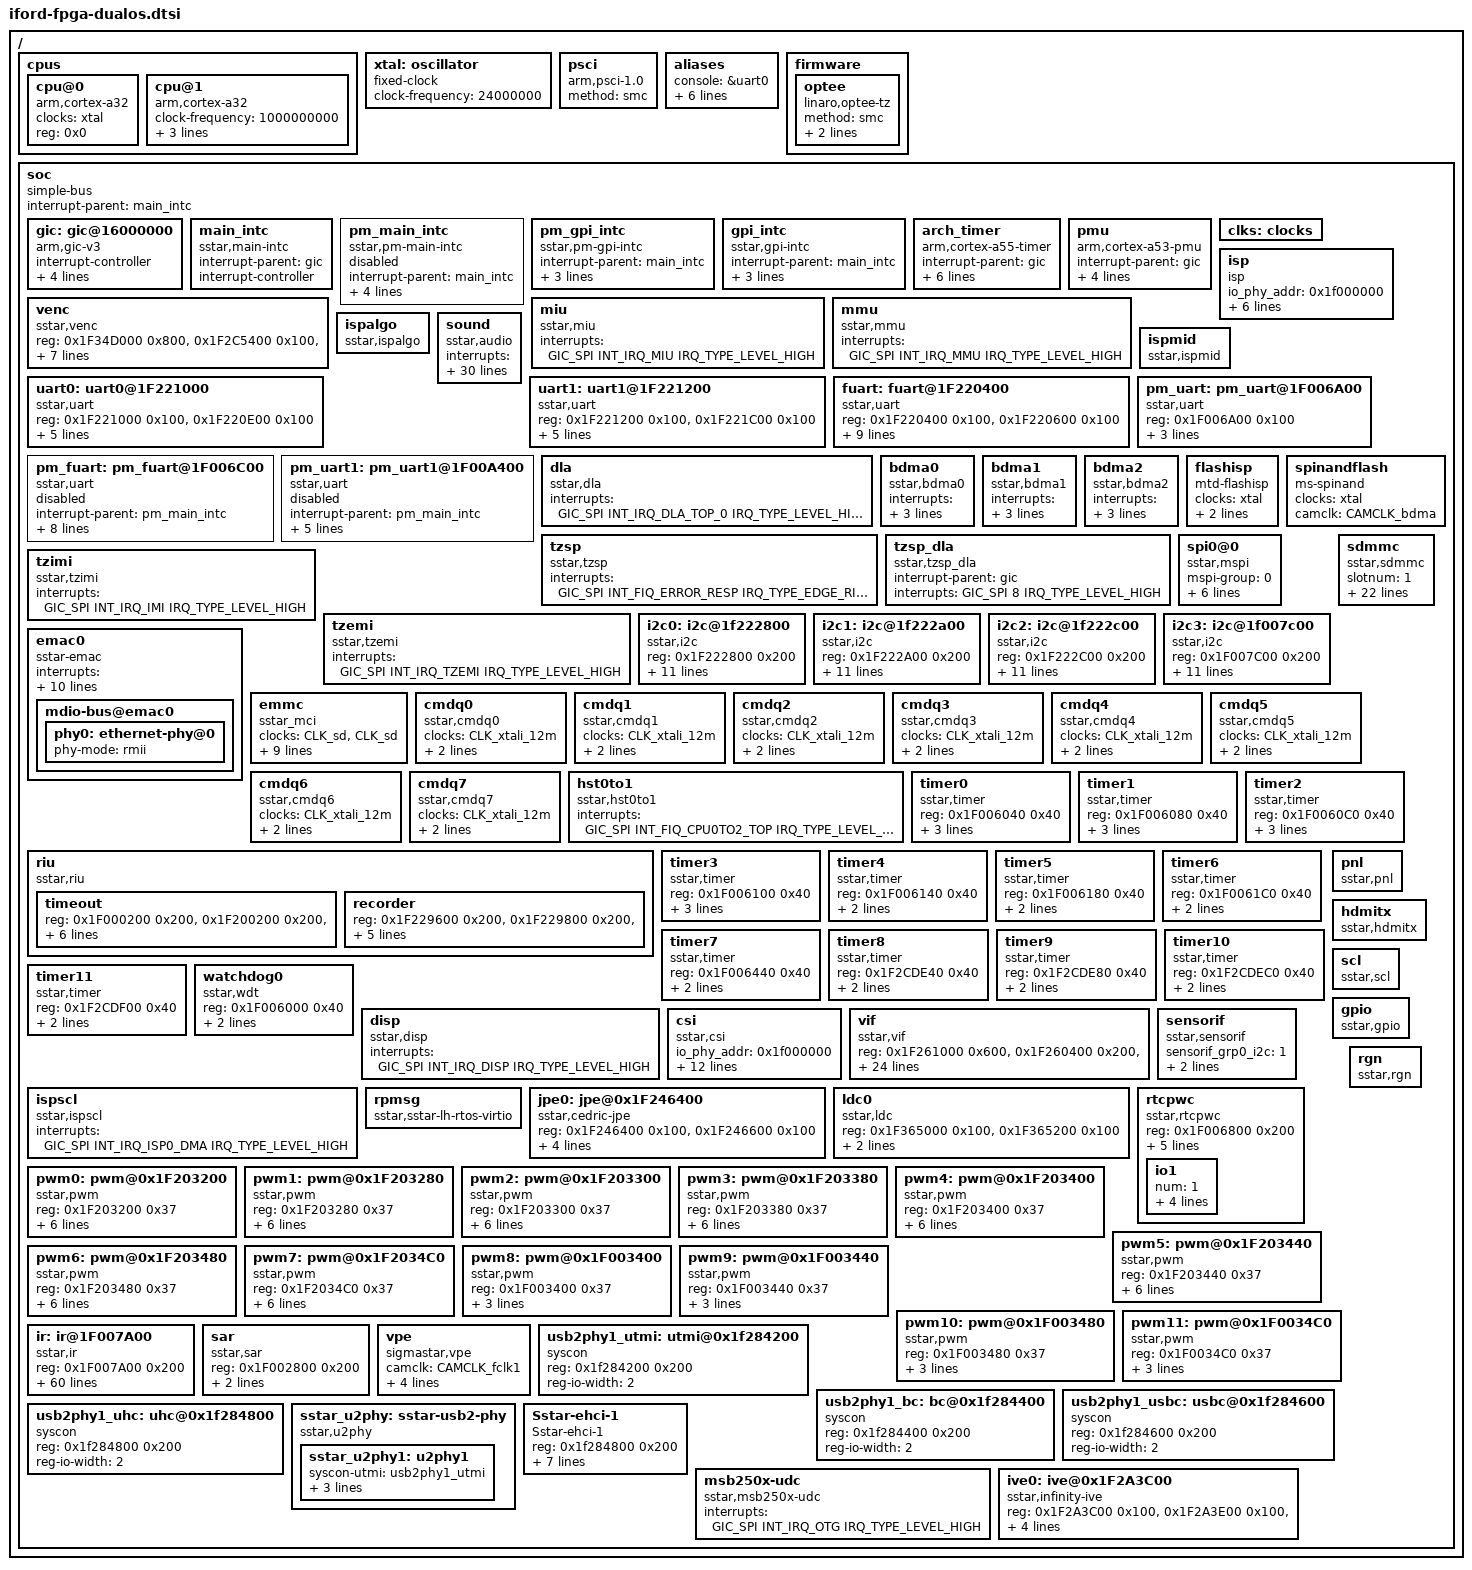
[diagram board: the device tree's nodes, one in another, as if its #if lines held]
/*
* iford-fpga.dtsi- Sigmastar
*
* Copyright (c) [2019~2020] SigmaStar Technology.
*
*
* This software is licensed under the terms of the GNU General Public
* License version 2, as published by the Free Software Foundation, and
* may be copied, distributed, and modified under those terms.
*
* This program is distributed in the hope that it will be useful,
* but WITHOUT ANY WARRANTY; without even the implied warranty of
* MERCHANTABILITY or FITNESS FOR A PARTICULAR PURPOSE.  See the
* GNU General Public License version 2 for more details.
*
*/
#include "../../../../include/generated/autoconf.h"
#include "../../../../drivers/sstar/include/iford/irqs-fpga.h"
#include "../../../../drivers/sstar/include/iford/pmsleep-irqs.h"
#include "../../../../drivers/sstar/include/iford/gpio.h"
#include <dt-bindings/interrupt-controller/irq.h>
#include <dt-bindings/interrupt-controller/arm-gic.h>
#include <dt-bindings/input/input.h>

/ {
    cpus {
        #address-cells = <1>;
        #size-cells = <0>;

        cpu@0 {
            device_type = "cpu";
            compatible = "arm,cortex-a32";
            clocks = <&xtal>;
            reg = <0x0>;
        };

#ifdef CONFIG_SMP
        cpu@1 {
            device_type = "cpu";
            compatible = "arm,cortex-a32";
            clock-frequency = <1000000000>;
            clocks = <&xtal>;
            reg = <0x1>;
#if CONFIG_ENABLE_METHOD_PSCI
            enable-method = "psci";
#endif
        };
#endif
    };

    xtal: oscillator {
        compatible = "fixed-clock";
        #clock-cells = <0>;
        clock-frequency = <24000000>;
    };

#if CONFIG_ARM_PSCI
    psci {
        compatible = "arm,psci-1.0";
        method = "smc";
    };
#endif

    aliases {
        console = &uart0;
        serial0 = &uart0;
        serial1 = &uart1;
        serial2 = &fuart;
        serial3 = &pm_uart;
        serial4 = &pm_fuart;
        serial5 = &pm_uart1;
    };

#ifdef CONFIG_OPTEE
    firmware {
        optee {
            compatible = "linaro,optee-tz";
            method = "smc";
            #interrupt-cells = <3>;
            interrupt-parent = <&gic>;
            interrupts = <GIC_SPI 31 IRQ_TYPE_EDGE_RISING>;
        };
    };
#endif

    soc {
        compatible = "simple-bus";
        interrupt-parent = <&main_intc>;
        #address-cells = <1>;
        #size-cells = <1>;
        ranges;

        gic: gic@16000000 {
            compatible = "arm,gic-v3";
            #interrupt-cells = <3>;
            #address-cells = <1>;
            #size-cells = <1>;
            interrupt-controller;
            interrupt-parent = <&gic>;
            redistributor-stride = <0x0 0x20000>;
            #redistributor-regions = <1>;
            reg = <0x16000000 0x20000>,
                  <0x16040000 0x40000>;
        };

        main_intc: main_intc {
            compatible = "sstar,main-intc";
            #interrupt-cells = <3>;
            #address-cells = <1>;
            #size-cells = <1>;
            interrupt-parent=<&gic>;
            interrupt-controller;
        };

        pm_main_intc: pm_main_intc {
            compatible = "sstar,pm-main-intc";
            #interrupt-cells = <1>;
            interrupt-parent=<&main_intc>;
            interrupt-controller;
            interrupts = <GIC_SPI INT_FIQ_FIQ_FROM_PM IRQ_TYPE_LEVEL_HIGH>, <GIC_SPI INT_IRQ_IRQ2HST_0 IRQ_TYPE_LEVEL_HIGH>;
            status = "disabled";
        };

        pm_gpi_intc: pm_gpi_intc {
            compatible = "sstar,pm-gpi-intc";
            #interrupt-cells = <1>;
            interrupt-parent=<&main_intc>;
            interrupt-controller;
            interrupts = <GIC_SPI INT_IRQ_PM_SLEEP IRQ_TYPE_LEVEL_HIGH>;
        };

        gpi_intc: gpi_intc {
            compatible = "sstar,gpi-intc";
            #interrupt-cells = <1>;
            interrupt-parent=<&main_intc>;
            interrupt-controller;
            interrupts = <GIC_SPI INT_IRQ_GPI_OUT IRQ_TYPE_LEVEL_HIGH>;
        };

        arch_timer {
            compatible = "arm,cortex-a55-timer", "arm,armv8-timer";
            interrupt-parent=<&gic>;
            interrupts = <GIC_PPI 13 (GIC_CPU_MASK_SIMPLE(2) | IRQ_TYPE_LEVEL_LOW)>,
                         <GIC_PPI 14 (GIC_CPU_MASK_SIMPLE(2) | IRQ_TYPE_LEVEL_LOW)>,
                         <GIC_PPI 11 (GIC_CPU_MASK_SIMPLE(2) | IRQ_TYPE_LEVEL_LOW)>,
                         <GIC_PPI 10 (GIC_CPU_MASK_SIMPLE(2) | IRQ_TYPE_LEVEL_LOW)>;
            clock-frequency = <6000000>;  /* arch_timer must use clock-frequency*/
        };

        pmu {
            compatible = "arm,cortex-a53-pmu";
            interrupt-parent=<&gic>;
            interrupts = <GIC_SPI 10 IRQ_TYPE_LEVEL_HIGH>,
                         <GIC_SPI 16 IRQ_TYPE_LEVEL_HIGH>,
                         <GIC_SPI 22 IRQ_TYPE_LEVEL_HIGH>,
                         <GIC_SPI 28 IRQ_TYPE_LEVEL_HIGH>;
        };

        clks: clocks{
            #address-cells = <1>;
            #size-cells = <1>;
            ranges;
        };
        venc {
            compatible = "sstar,venc";
            reg = <0x1F34D000 0x800>, <0x1F2C5400 0x100>, <0x1F203C00 0x100>, <0x1F207800 0x100>, <0x1F2C5400 0x100>;
            reg-names = "vpu-bit", "venc-brige", "hw-uart0", "hw-uart1", "venc-gp";
            interrupts = <GIC_SPI INT_IRQ_MHE_0 IRQ_TYPE_LEVEL_HIGH>;
            interrupt-parent = <&main_intc>;
            interrupt-names = "mhe-irq";
            clocks = <&CLK_vhe>, <&CLK_mfe>, <&CLK_ven_axi>,<&CLK_ven_scdn>,<&CLK_ven_sc_if>;
            clock-names = "CKG_venc";
            status = "ok";
        };

        miu {
            compatible = "sstar,miu";
            interrupts=<GIC_SPI INT_IRQ_MIU IRQ_TYPE_LEVEL_HIGH>;
            status = "ok";
        };

        mmu {
            compatible = "sstar,mmu";
            interrupts=<GIC_SPI INT_IRQ_MMU IRQ_TYPE_LEVEL_HIGH>;
            status = "ok";
        };

        isp: isp {
            compatible = "isp";
            io_phy_addr = <0x1f000000>;
            banks = <0x1302>;
            interrupts = <GIC_SPI INT_IRQ_ISP_0 IRQ_TYPE_LEVEL_HIGH>;
            clocks = <&CLK_isp>,<&CLK_fclk1>,<&CLK_dsc_enc1>,<&CLK_dsc_dec1>;
            status = "ok";
            clock-frequency-index = <0>;
        };

        ispalgo: ispalgo {
            compatible = "sstar,ispalgo";
            status = "ok";
        };

/*
        ispscl: ispscl {
            compatible = "sstar,ispscl";
            interrupts = <GIC_SPI INT_IRQ_ISP0_DMA IRQ_TYPE_LEVEL_HIGH>;
            status = "ok";
        };
*/

        ispmid: ispmid {
            compatible = "sstar,ispmid";
            status = "ok";
        };

/*
        timer_clockevent: timer@1F006040 {
            compatible = "sstar,piu-clockevent";
            reg = <0x1F006040 0x100>;
            interrupts=<GIC_SPI INT_FIQ_TIMER_0 IRQ_TYPE_LEVEL_HIGH>;
            clocks = <&CLK_xtali_12m>;
        };
*/
        sound {
            compatible = "sstar,audio";
            interrupts=<GIC_SPI INT_IRQ_BACH IRQ_TYPE_LEVEL_HIGH>;
            amp-pad = <PAD_GPIO2 1 PAD_GPIO2 1>;
            clocks = <&CLK_au_sys_384>;
#ifdef CONFIG_CAM_CLK
            camclk = <CAMCLK_bach>;
#endif
            // padmux
            digmic-padmux = <5>;
            i2s-trx-shared-padmux = <0>; //for 4-wired mode panmux
            i2s-tx-padmux = <6>; //6-wired mode
            i2s-rx-padmux = <7>; //6-wired mode
            i2s-mck-padmux = <7>;

            keep-i2s-clk = <0>;
            i2s-pcm = <0>;
            i2s-rx-mode = <0>;

            // I2S RX TDM
            i2s-rx-tdm-ws-pgm = <0>;   // 0: OFF  1: ON
            i2s-rx-tdm-ws-width = <0>; // value: 0~31 (width = value + 1)
            i2s-rx-tdm-ws-inv = <0>;   // 0: normal  1: inverse WCK
            i2s-rx-tdm-bck-inv = <0>;  // 0: normal  1: inverse BCK
            i2s-rx-tdm-ch-swap = <0 0 0 0>; // 0: OFF  1: ON

            // I2S TX TDM
            i2s-tx-tdm-ws-pgm = <0>;   // 0: OFF  1: ON
            i2s-tx-tdm-ws-width = <0>; // value: 0~31 (width = value + 1)
            i2s-tx-tdm-ws-inv = <0>;   // 0: normal  1: inverse WCK
            i2s-tx-tdm-bck-inv = <0>;  // 0: normal  1: inverse BCK
            i2s-tx-tdm-ch-swap = <0 0 0 0>; // 0: OFF  1: ON
            i2s-tx-tdm-active-slot = <0xFFFF>; // value: 0x00 ~ 0xFF (bit0->slot0, bit1->slot1, ... )

            // dmic bck mode
            dmic-bck-mode-8k = <3>;    //2.4M
            dmic-bck-mode-16k = <6>;   //2.4M
            dmic-bck-mode-32k = <9>;   //4.8M
            dmic-bck-mode-48k = <11>;  //4.8M
            // dmic bck ext mode
            dmic-bck-ext-mode = <0>;   //share with i2s rx bck

            // hpf default level
            hpf-adc1-dmic2ch-level = <1 0xf>;//1:use this level 0: not use this level; 0xf:hpf level 0~0xf
            hpf-dmic4ch-level      = <1 0x0>;

            status = "ok";
        };

        uart0: uart0@1F221000 {
            compatible = "sstar,uart";
            reg = <0x1F221000 0x100>, <0x1F220E00 0x100>;
            interrupts= <GIC_SPI INT_IRQ_FUART0 IRQ_TYPE_LEVEL_HIGH>, <GIC_SPI INT_IRQ_FUART0_MERGE IRQ_TYPE_LEVEL_HIGH>;
            clocks = <&xtal>;
            dma = <0>;
            status = "okay";
        };

        uart1: uart1@1F221200 {
            compatible = "sstar,uart";
            reg = <0x1F221200 0x100>, <0x1F221C00 0x100>;
            interrupts= <GIC_SPI INT_IRQ_FUART1 IRQ_TYPE_LEVEL_HIGH>, <GIC_SPI INT_IRQ_FUART1_MERGE IRQ_TYPE_LEVEL_HIGH>;
            clocks = <&xtal>;
            dma = <0>;
            status = "okay";
        };

        fuart: fuart@1F220400 {
            compatible = "sstar,uart";
            reg = <0x1F220400 0x100>, <0x1F220600 0x100>;
            interrupts= <GIC_SPI INT_IRQ_FUART IRQ_TYPE_LEVEL_HIGH>, <GIC_SPI INT_IRQ_FUART_MERGE IRQ_TYPE_LEVEL_HIGH>;
            clocks = <&xtal>;
            dma = <0>;
            sctp_enable = <0>;
            rx_fifo_level = <0>;
            tx_fifo_level = <0>;
            digmux = <0xFF>;
            status = "okay";
        };

        pm_uart: pm_uart@1F006A00 {
            compatible = "sstar,uart";
            reg = <0x1F006A00 0x100>;
            interrupts= <GIC_SPI INT_IRQ_PM_UART IRQ_TYPE_LEVEL_HIGH>;
            clocks = <&xtal>;
            status = "okay";
        };

        pm_fuart: pm_fuart@1F006C00 {
            interrupt-parent = <&pm_main_intc>;
            compatible = "sstar,uart";
            reg = <0x1F006C00 0x100>, <0x1F006E00 0x100>;
            interrupts= <INT_PMSLEEP_IRQ_PM_FUART>, <INT_PMSLEEP_IRQ_PM_FUART_MERGE>;
            clocks = <&xtal>;
            dma = <0>;
            sctp_enable = <0>;
            rx_fifo_level = <0>;
            tx_fifo_level = <0>;
            status = "disabled";
        };

        pm_uart1: pm_uart1@1F00A400 {
            interrupt-parent = <&pm_main_intc>;
            compatible = "sstar,uart";
            reg = <0x1F00A400 0x100>, <0x1F00A600 0x100>;
            interrupts= <INT_PMSLEEP_IRQ_PM_FUART1>, <INT_PMSLEEP_IRQ_PM_FUART1_MERGE>;
            clocks = <&xtal>;
            dma = <0>;
            status = "disabled";
        };

        dla {
            compatible = "sstar,dla";
            interrupts = <GIC_SPI INT_IRQ_DLA_TOP_0 IRQ_TYPE_LEVEL_HIGH>;
            status = "ok";
        };

        bdma0 {
            compatible = "sstar,bdma0";
            interrupts=<GIC_SPI INT_IRQ_BDMA IRQ_TYPE_LEVEL_HIGH>;
            reg = <0x1F200400 0x100>;
            clocks = <&xtal>;
            status = "ok";
        };

        bdma1 {
            compatible = "sstar,bdma1";
            interrupts=<GIC_SPI INT_IRQ_BDMA_2 IRQ_TYPE_LEVEL_HIGH>;
            reg = <0x1F201600 0x100>;
            clocks = <&xtal>;
            status = "ok";
        };

        bdma2 {
            compatible = "sstar,bdma2";
            interrupts=<GIC_SPI INT_IRQ_PM_BDMA IRQ_TYPE_LEVEL_HIGH>;
            reg = <0x1F008A00 0x100>;
            clocks = <&xtal>;
            status = "ok";
        };

        /*
        xordma {
            compatible = "sstar,xordma";
            interrupts = <GIC_SPI INT_IRQ_BDMA_3 IRQ_TYPE_LEVEL_HIGH>;
            reg = <0x1F200C00 0x100>,<0x1F201800 0x100>;
            clocks = <&xtal>;
            status = "ok";
        };
        */
#ifdef CONFIG_OPTEE
        tzsp {
            compatible = "sstar,tzsp";
            interrupts=<GIC_SPI INT_FIQ_ERROR_RESP IRQ_TYPE_EDGE_RISING>;
            status = "ok";
        };
        tzsp_dla {
            compatible = "sstar,tzsp_dla";
            interrupt-parent=<&gic>;
            interrupts = <GIC_SPI 8 IRQ_TYPE_LEVEL_HIGH>;
        };
        tzimi {
            compatible = "sstar,tzimi";
            interrupts=<GIC_SPI INT_IRQ_IMI IRQ_TYPE_LEVEL_HIGH>;
            status = "ok";
        };
        tzemi {
            compatible = "sstar,tzemi";
            interrupts=<GIC_SPI INT_IRQ_TZEMI IRQ_TYPE_LEVEL_HIGH>;
            status = "ok";
        };
#endif
        flashisp {
            compatible = "mtd-flashisp";
            clocks = <&xtal>;
        #ifdef CONFIG_CAM_CLK
            camclk = <CAMCLK_bdma>;
        #endif
            quadread = <0>;
            status = "ok";
        };

        spinandflash {
            compatible = "ms-spinand";
            clocks =<&xtal>;
#ifdef CONFIG_CAM_CLK
            camclk = <CAMCLK_bdma>;
#endif
            status = "ok";
        };

        spi0@0{
            compatible = "sstar,mspi";
            mspi-group = <0>;
#ifdef CONFIG_CAM_CLK
            camclk = <CAMCLK_mspi0>;
#else
            clocks = <&CLK_mspi0>;
#endif
            reg = <0x1F222000 0x200>;
            interrupts = <GIC_SPI INT_IRQ_MSPI_0 IRQ_TYPE_LEVEL_HIGH>;
            use-dma = <1>;
            cs-num = <1>;
            //cs-ext = <PAD_UNKNOWN>;
            //4to3-mode;
            //clk-out-mode = <27000000>;
            status = "ok";
        };

        i2c0: i2c@1f222800 {
            compatible = "sstar,i2c";
            reg = <0x1F222800 0x200>;
            #address-cells = <1>;
            #size-cells = <0>;
            interrupts = <GIC_SPI INT_IRQ_MIIC IRQ_TYPE_LEVEL_HIGH>;
            clocks = <&CLK_miic0>;
            group = <0>;
            dma_en = <1>;
            speed = <400000>;
            //if u want set tSU/tHD, do not set 0, tSU = (t-su-* / i2c-srcclk)S, tHD = (t-hd-* / i2c-srcclk)S
            t-su-sta = <0>;
            t-hd-sta = <0>;
            t-su-sto = <0>;
            t-hd-sto = <0>;
            //1->open drain; 2->open drain + one push; 3->open drain + one push + clock push; 4->push-pull
            output-mode = <2>;
            status = "ok";
        };

        i2c1: i2c@1f222a00 {
            compatible = "sstar,i2c";
            reg = <0x1F222A00 0x200>;
            #address-cells = <1>;
            #size-cells = <0>;
            interrupts = <GIC_SPI INT_IRQ_MIIC IRQ_TYPE_LEVEL_HIGH>;
            clocks = <&CLK_miic1>;
            group = <1>;
            dma_en = <1>;
            speed = <400000>;
            t-su-sta = <0>;
            t-hd-sta = <0>;
            t-su-sto = <0>;
            t-hd-sto = <0>;
            output-mode = <2>;
            status = "ok";
        };

        #if !defined(CONFIG_OPTEE)
        i2c2: i2c@1f222c00 {
            compatible = "sstar,i2c";
            reg = <0x1F222C00 0x200>;
            #address-cells = <1>;
            #size-cells = <0>;
            interrupts = <GIC_SPI INT_IRQ_MIIC2 IRQ_TYPE_LEVEL_HIGH>;
            clocks = <&CLK_miic2>;
            group = <2>;
            dma_en = <1>;
            speed = <400000>;
            t-su-sta = <0>;
            t-hd-sta = <0>;
            t-su-sto = <0>;
            t-hd-sto = <0>;
            output-mode = <2>;
            status = "ok";
        };
        #endif

        i2c3: i2c@1f007c00 {
            compatible = "sstar,i2c";
            reg = <0x1F007C00 0x200>;
            #address-cells = <1>;
            #size-cells = <0>;
            interrupts = <GIC_SPI INT_IRQ_PM_MIIC0 IRQ_TYPE_LEVEL_HIGH>;
            //clocks = <&CLK_pm_miic>;
            clocks = <&CLK_miic2>;//debug
            group = <3>;
            dma_en = <1>;
            speed = <400000>;
            t-su-sta = <0>;
            t-hd-sta = <0>;
            t-su-sto = <0>;
            t-hd-sto = <0>;
            output-mode = <2>;
            status = "ok";
        };

        emac0: emac0 {
            compatible = "sstar-emac";
            interrupts = <GIC_SPI INT_IRQ_EMAC IRQ_TYPE_LEVEL_HIGH>, <GIC_SPI INT_FIQ_LAN_ESD IRQ_TYPE_LEVEL_HIGH>, <GIC_SPI INT_IRQ_EMAC_SCATTER IRQ_TYPE_LEVEL_HIGH>;
            // clocks = <&CLK_emac_ahb>,<&CLK_emac_tx>,<&CLK_emac_rx>;
            // reg = <0x1F2A2000 0x800>, <0x1F343C00 0x600>, <0x1F006200 0x600>;
            reg = <0x1F2A2000 0x800>, <0x1F304200 0x600>, <0x00000000 0x000>;
            pad = <0x1F203C38 0x0001 0x0001>; // pad selection from 0x0001
            bus-mode = <2>;//1:MII 2:RMII
            led-invert = <0>;//switch led from high-level lighting to low-level lighting
            phy-handle = <&phy0>;
            max-speed = <10>;
            status = "ok";
            mdio-bus@emac0 {
                phy0: ethernet-phy@0 {
                    phy-mode = "rmii";
                    //phy-mode = "mii";
                };
            };
        };

        emmc {
            compatible = "sstar_mci";
            clocks =<&CLK_sd>, <&CLK_sd>;//, <&CLK_sdio2>;
            clock-names = "clk_fcie0", "clk_fcie1";
            interrupts =  <GIC_SPI INT_IRQ_SD IRQ_TYPE_LEVEL_HIGH>,
                          <GIC_SPI INT_IRQ_SDIO IRQ_TYPE_LEVEL_HIGH>;
            slot-num = <1>;
            adma-mode = <1>,<1>,<1>;
            ip-select = <0>,<1>,<2>;
            pad-select = <1>,<1>,<0>;
            bus-width = <4>,<4>,<4>;
            max-clks = <48000000>,<48000000>,<48000000>;
            status = "ok";
        };

        sdmmc {
            compatible = "sstar,sdmmc";

            slotnum = <1>;
            revcdz = <0>;

            slot-ip-orders = <0>,<1>,<2>;
            slot-pad-orders = <0>,<0>,<2>;
            slot-max-clks = <48000000>,<48000000>,<48000000>;
            slot-intcdzs = <1>,<1>,<1>;
            slot-fakecdzs = <0>,<0>,<0>;
            // slot-cdzs-pad = <PAD_PM_SD_CDZ>,<PAD_PM_GPIO8>,<0>;
            // slot-pwr-pad = <PAD_FUART_RTS>,<PAD_PM_GPIO7>,<0>;
            slot-pwr-off-delay = <30>,<30>,<30>;
            slot-pwr-on-delay = <1>,<1>,<1>;
            slot-removable = <1>,<1>,<1>;
            slot-sdio-use = <0>,<0>,<0>;
            slot-sdio-use-1bit = <0>,<0>,<0>;
            slot-sdio-dis-intr = <0>,<0>,<0>;
            slot-en-clk-phase = <0>,<0>,<0>; //0/1
            slot-tx-clk-phase = <0>,<0>,<0>; //0-3
            slot-rx-clk-phase = <0>,<0>,<0>; //0-3

            interrupts-extended = <&main_intc GIC_SPI INT_IRQ_SD IRQ_TYPE_LEVEL_HIGH>,//was INT_IRQ_SDIO
                                  <&main_intc GIC_SPI INT_IRQ_SDIO IRQ_TYPE_LEVEL_HIGH>,
                                  <&main_intc GIC_SPI INT_FIQ_SD_CDZ_0 IRQ_TYPE_LEVEL_HIGH>,
                                  //<&ms_gpi_intc 42>,
                                  <&main_intc GIC_SPI INT_FIQ_PAD2SDIO_SD_CDZ IRQ_TYPE_LEVEL_HIGH>,
                                  <&main_intc GIC_SPI INT_FIQ_SD_CDZ_0 IRQ_TYPE_LEVEL_HIGH>;
            interrupt-names = "mie0_irq", "mie1_irq", "cdz_slot0_irq", "cdz_slot1_irq", "cdz_slot2_irq";
            clocks = <&CLK_sd>,<&CLK_sd>;
            status = "ok";
        };

        cmdq0 {
            compatible = "sstar,cmdq0";
            clocks = <&CLK_xtali_12m>; //for timeout tick
            interrupts=<GIC_SPI INT_IRQ_CMDQ IRQ_TYPE_LEVEL_HIGH>;
            status = "ok";
        };

        cmdq1 {
            compatible = "sstar,cmdq1";
            clocks = <&CLK_xtali_12m>; //for timeout tick
            interrupts=<GIC_SPI INT_IRQ_CMDQ IRQ_TYPE_LEVEL_HIGH>;
            status = "ok";
        };

        cmdq2 {
            compatible = "sstar,cmdq2";
            clocks = <&CLK_xtali_12m>; //for timeout tick
            interrupts=<GIC_SPI INT_IRQ_CMDQ IRQ_TYPE_LEVEL_HIGH>;
            status = "ok";
        };

        cmdq3 {
            compatible = "sstar,cmdq3";
            clocks = <&CLK_xtali_12m>; //for timeout tick
            interrupts=<GIC_SPI INT_IRQ_CMDQ IRQ_TYPE_LEVEL_HIGH>;
            status = "ok";
        };

        cmdq4 {
            compatible = "sstar,cmdq4";
            clocks = <&CLK_xtali_12m>; //for timeout tick
            interrupts=<GIC_SPI INT_IRQ_CMDQ_1 IRQ_TYPE_LEVEL_HIGH>;
            status = "ok";
        };

        cmdq5 {
            compatible = "sstar,cmdq5";
            clocks = <&CLK_xtali_12m>; //for timeout tick
            interrupts=<GIC_SPI INT_IRQ_CMDQ_1 IRQ_TYPE_LEVEL_HIGH>;
            status = "ok";
        };

        cmdq6 {
            compatible = "sstar,cmdq6";
            clocks = <&CLK_xtali_12m>; //for timeout tick
            interrupts=<GIC_SPI INT_IRQ_CMDQ_1 IRQ_TYPE_LEVEL_HIGH>;
            status = "ok";
        };

        cmdq7 {
            compatible = "sstar,cmdq7";
            clocks = <&CLK_xtali_12m>; //for timeout tick
            interrupts=<GIC_SPI INT_IRQ_CMDQ_1 IRQ_TYPE_LEVEL_HIGH>;
            status = "ok";
        };

        hst0to1 {
            compatible = "sstar,hst0to1"; // mailbox int
            interrupts = <GIC_SPI INT_FIQ_CPU0TO2_TOP IRQ_TYPE_LEVEL_HIGH>;
            status = "ok";
        };

        riu {
            #address-cells = <1>;
            #size-cells = <1>;
            compatible = "sstar,riu";
            ranges;
            status = "ok";

            timeout {
                reg = <0x1F000200 0x200>, <0x1F200200 0x200>, <0x1F2CE000 0x200>;
                interrupts = <GIC_SPI INT_FIQ_PM_XIU_TIMEOUT IRQ_TYPE_LEVEL_HIGH>, <GIC_SPI INT_FIQ_XIU_TIMEOUT IRQ_TYPE_LEVEL_HIGH>,
                             <GIC_SPI INT_FIQ_XIU_XIU_TIMEOUT IRQ_TYPE_LEVEL_HIGH>;
                print-on;
                //bug-on;
                status = "ok";
            };

            recorder {
                reg = <0x1F229600 0x200>, <0x1F229800 0x200>, <0x1F229A00 0x200>, <0x1F229C00 0x200>;
                interrupts = <GIC_SPI INT_IRQ_RIU_RECORDING IRQ_TYPE_LEVEL_HIGH>;
                clocks = <&CLK_xtali>;
                print-on;
                //bug-on;
                status = "ok";
            };
        };

        timer0 {
            compatible = "sstar,timer";
            reg = <0x1F006040 0x40>;
            interrupts = <GIC_SPI INT_FIQ_TIMER IRQ_TYPE_LEVEL_HIGH>;
            clocks = <&CLK_mpll_288m_div8>;
            status = "ok";
        };

        timer1 {
            compatible = "sstar,timer";
            reg = <0x1F006080 0x40>;
            interrupts = <GIC_SPI INT_FIQ_TIMER IRQ_TYPE_LEVEL_HIGH>;
            clocks = <&CLK_mpll_288m_div8>;
            status = "ok";
        };

        timer2 {
            compatible = "sstar,timer";
            reg = <0x1F0060C0 0x40>;
            interrupts = <GIC_SPI INT_FIQ_TIMER IRQ_TYPE_LEVEL_HIGH>;
            clocks = <&CLK_mpll_288m_div8>;
            status = "ok";
        };

        timer3 {
            compatible = "sstar,timer";
            reg = <0x1F006100 0x40>;
            interrupts = <GIC_SPI INT_FIQ_TIMER IRQ_TYPE_LEVEL_HIGH>;
            clocks = <&CLK_mpll_288m_div8>;
            status = "ok";
        };

        timer4 {
            compatible = "sstar,timer";
            reg = <0x1F006140 0x40>;
            interrupts = <GIC_SPI INT_FIQ_TIMER IRQ_TYPE_LEVEL_HIGH>;
            status = "ok";
        };

        timer5 {
            compatible = "sstar,timer";
            reg = <0x1F006180 0x40>;
            interrupts = <GIC_SPI INT_FIQ_TIMER IRQ_TYPE_LEVEL_HIGH>;
            status = "ok";
        };

        timer6 {
            compatible = "sstar,timer";
            reg = <0x1F0061C0 0x40>;
            interrupts = <GIC_SPI INT_FIQ_TIMER IRQ_TYPE_LEVEL_HIGH>;
            status = "ok";
        };

        timer7 {
            compatible = "sstar,timer";
            reg = <0x1F006440 0x40>;
            interrupts = <GIC_SPI INT_FIQ_TIMER IRQ_TYPE_LEVEL_HIGH>;
            status = "ok";
        };

        timer8 {
            compatible = "sstar,timer";
            reg = <0x1F2CDE40 0x40>;
            interrupts = <GIC_SPI INT_FIQ_NONPM_TIMER_0 IRQ_TYPE_LEVEL_HIGH>;
            status = "ok";
        };

        timer9 {
            compatible = "sstar,timer";
            reg = <0x1F2CDE80 0x40>;
            interrupts = <GIC_SPI INT_FIQ_NONPM_TIMER_1 IRQ_TYPE_LEVEL_HIGH>;
            status = "ok";
        };

        timer10 {
            compatible = "sstar,timer";
            reg = <0x1F2CDEC0 0x40>;
            interrupts = <GIC_SPI INT_FIQ_NONPM_TIMER_2 IRQ_TYPE_LEVEL_HIGH>;
            status = "ok";
        };

        timer11 {
            compatible = "sstar,timer";
            reg = <0x1F2CDF00 0x40>;
            interrupts = <GIC_SPI INT_FIQ_NONPM_TIMER_3 IRQ_TYPE_LEVEL_HIGH>;
            status = "ok";
        };

        watchdog0 {
            compatible = "sstar,wdt";
            reg = <0x1F006000 0x40>;
            interrupts = <GIC_SPI INT_FIQ_WDT IRQ_TYPE_LEVEL_HIGH>;
            status = "ok";
        };

        pnl: pnl {
            compatible = "sstar,pnl";
            status = "ok";
        };

        disp: disp {
            compatible = "sstar,disp";
            status = "ok";
            //clocks = <&CLK_mop0>, <&CLK_mop1>, <&CLK_mop2>, <&CLK_disp_432>, <&CLK_disp_216>;
            interrupts = <GIC_SPI INT_IRQ_DISP IRQ_TYPE_LEVEL_HIGH>;
            //Reg = <0x1F224000 0x200>;
        };

        hdmitx: hdmitx {
            compatible = "sstar,hdmitx";
            status = "ok";
           // clocks = <&CLK_disp_432>;
            //i2c_id = <0>;
            //hpd_gpio = <131>;
            //i2c_sw = <1>;
            //i2c_sda_gpio = <132>;
            //i2c_scl_gpio = <133>;
            //Reg = <0x1F224000 0x200>;
        };

        csi: csi {
            compatible = "sstar,csi";
            io_phy_addr = <0x1f000000>;
            banks = <0x153C>,<0x153D>,<0x153E>,<0x1538>,<0x153A>,<0x153B>;
            atop_banks = <0x153F>;
            clkgen_banks = <0x1038>;
            interrupts=  <GIC_SPI INT_IRQ_MIPI_CSI2 IRQ_TYPE_LEVEL_HIGH>;
            //clocks = <&CLK_csi_mac_lptx_top_i_m00>,<&CLK_csi_mac_top_i_m00>,<&CLK_ns_top_i_m00>,<&CLK_csi_mac_lptx_top_i_m1>,<&CLK_csi_mac_top_i_m1>,<&CLK_ns_top_i_m1>,<&CLK_csi_mac_lptx_top_i_m01>,<&CLK_csi_mac_top_i_m01>,<&CLK_ns_top_i_m01>;
            //clocks = <&CLK_csi_mac_lptx_top_i_m00>,<&CLK_csi_mac_top_i_m00>,<&CLK_ns_top_i_m00>,<&CLK_csi_mac_lptx_top_i_m01>,<&CLK_csi_mac_top_i_m01>,<&CLK_ns_top_i_m01>;
            status = "ok";
            /* Config max lane number */
            csi_sr0_lane_num = <4>;
            csi_sr2_lane_num = <2>;
            /* Config lane selection */
            csi_sr0_lane_select = <2 4 3 1 0>;
            csi_sr2_lane_select = <2 1 0>;
            /* Config lane P/N swap */
            csi_sr0_lane_pn_swap = <1 1 1 1 1>;
            csi_sr2_lane_pn_swap = <1 1 1>;
        };

        vif: vif {
            compatible = "sstar,vif";
            status = "ok";
            reg = <0x1F261000 0x600>, <0x1F260400 0x200>, <0x1F260600 0x200>, <0x1F207C00 0x200>, <0x1F207800 0x200>, <0x1F227400 0x200>, <0x1F207000 0x200>, <0x1F207E00 0x200>,<0x1F000000 0x400000>, <0x1F203C00 0x200>;
            //clocks = <&CLK_sr00_mclk>,<&CLK_sr1_mclk>,<&CLK_sr01_mclk>;
            interrupts = <GIC_SPI INT_IRQ_ISP0_VIF IRQ_TYPE_LEVEL_HIGH>;
            /* Config sensor 0 pad mux */
            vif_sr0_mipi_mode         = <1>;
            vif_sr0_mipi_ctrl_mode    = <1>;
            vif_sr0_mipi_rst_mode     = <0>;
            vif_sr0_mipi_pdn_mode     = <0>;
            vif_sr0_mipi_mclk_mode    = <0>;

            /* Config sensor 1 pad mux */
            vif_sr0_par_mode          = <1>;
            vif_sr0_par_ctrl_mode     = <2>;
            vif_sr0_par_rst_mode      = <0>;
            vif_sr0_par_pdn_mode      = <0>;
            vif_sr0_par_mclk_mode     = <0>;

            /* Config sensor 2 pad mux */
            vif_sr2_mipi_mode         = <1>;
            vif_sr2_mipi_ctrl_mode    = <1>;
            vif_sr2_mipi_rst_mode     = <0>;
            vif_sr2_mipi_pdn_mode     = <0>;
            vif_sr2_mipi_mclk_mode    = <0>;

            /* Config mclk 37.125MHz supported */
            vif_sr0_mclk_37p125 = <1>;
            vif_sr1_mclk_37p125 = <1>;
            vif_sr2_mclk_37p125 = <1>;
        };

        ispscl: ispscl {
            compatible = "sstar,ispscl";
            interrupts = <GIC_SPI INT_IRQ_ISP0_DMA IRQ_TYPE_LEVEL_HIGH>;
            status = "ok";
        };
        sensorif: sensorif {
            compatible = "sstar,sensorif";
            status = "ok";
            sensorif_grp0_i2c = <1>;
            sensorif_grp1_i2c = <2>;
            sensorif_grp2_i2c = <1>;
        };
#if defined(CONFIG_SSTAR_LH_RTOS_VIRTIO)
        rpmsg: rpmsg {
            compatible = "sstar,sstar-lh-rtos-virtio";
        };
#endif
        jpe0: jpe@0x1F246400 {
            compatible = "sstar,cedric-jpe";
            reg = <0x1F246400 0x100>, <0x1F246600 0x100>;
            interrupts = <GIC_SPI INT_IRQ_JPE IRQ_TYPE_LEVEL_HIGH>;
            clocks = <&CLK_jpe>;
            clock-names = "CKG_jpe";
            interrupt-names = "jpe-irq0";
            clk-select = <0>; // 0: 480M  1: 432MHz  2: 384MHz  3: 320MHz 4: 288MHz 5:216MHz
            status = "ok";
        };

        ldc0: ldc0 {
            compatible = "sstar,ldc";
            reg = <0x1F365000 0x100>, <0x1F365200 0x100>;
            interrupts=<GIC_SPI INT_IRQ_LDC_FEYE_0 IRQ_TYPE_LEVEL_HIGH>;
            status = "ok";
        };

        scl: scl {
            compatible = "sstar,scl";
            status = "ok";
        };

        gpio: gpio {
            compatible = "sstar,gpio";
            status = "ok";
        };

        rtcpwc: rtcpwc {
            compatible = "sstar,rtcpwc";
            reg = <0x1F006800 0x200>;
            interrupts=<GIC_SPI INT_IRQ_FLAG_POC IRQ_TYPE_LEVEL_HIGH>;
            // io0-hiz;
            // io2-wos = <1>;           //0:CMPHL 1:CMPHL 2:CMPL 3:CMPH
            // io2-wos-v = <0x2 0x3>;   //<vl vh> 0<vl<8 0<vh<8
            // io3-pu;
            // offset-count = <100>;
            // offset-nagative;
            // iso-auto-regen;
            /*
             * io4 control source selection
             * io0/io1/io2/io3 ctrl bit0
             * alarm ctrl           bit1
             * sw ctrl              bit2
             * support the combination of above ways
             */
            io4-enable = <7>;
            /*
             * io5 control source selection
             * io4 ctrl    bit0
             * alarm ctrl  bit1
             * sw ctrl     bit2
             * support the combination of above ways
             */
            io5-enable = <7>;   // for demo board,use 3,default hight
            // io5-no-poweroff;    // io5 keep when excute 'poweroff' use for wakeup pm51
            status = "ok";

#ifdef CONFIG_SSTAR_PWC_IO_POLLING
            poll-interval = <10>;
#endif /* CONFIG_SSTAR_PWC_IO_POLLING */
            io1 {
                num = <1>;
                keycode = <KEY_WAKEUP>;
#ifdef CONFIG_SSTAR_PWC_IO_POLLING
                debounce-interval = <10>;
#endif /* CONFIG_SSTAR_PWC_IO_POLLING */
#ifdef CONFIG_SSTAR_PWC_IO_INTERRUPT
                interrupt-parent = <&sstar_pm_gpi_intc>;
                interrupts = <INT_PM_GPI_FIQ_PAD_RTC_IO1>;
#endif /* CONFIG_SSTAR_PWC_IO_INTERRUPT */
            };
        };

        pwm0: pwm@0x1F203200{
            compatible = "sstar,pwm";
            reg = <0x1F203200 0x37>;
            #pwm-cells = <3>;
            channel = <0>;
            group = <0>;
            clocks = <&CLK_pwm>;
            clk-select = <0>;
            interrupts=<GIC_SPI INT_IRQ_PWM IRQ_TYPE_LEVEL_HIGH>;
            status = "ok";
        };

        pwm1: pwm@0x1F203280 {
            compatible = "sstar,pwm";
            reg = <0x1F203280 0x37>;
            #pwm-cells = <3>;
            channel = <1>;
            group = <0>;
            clocks = <&CLK_pwm>;
            clk-select = <0>;
            interrupts=<GIC_SPI INT_IRQ_PWM IRQ_TYPE_LEVEL_HIGH>;
            status = "ok";
        };

        pwm2: pwm@0x1F203300 {
            compatible = "sstar,pwm";
            reg = <0x1F203300 0x37>;
            #pwm-cells = <3>;
            channel = <2>;
            group = <0>;
            clocks = <&CLK_pwm>;
            clk-select = <0>;
            interrupts=<GIC_SPI INT_IRQ_PWM IRQ_TYPE_LEVEL_HIGH>;
            status = "ok";
        };

        pwm3: pwm@0x1F203380 {
            compatible = "sstar,pwm";
            reg = <0x1F203380 0x37>;
            #pwm-cells = <3>;
            channel = <3>;
            group = <0>;
            clocks = <&CLK_pwm>;
            clk-select = <0>;
            interrupts=<GIC_SPI INT_IRQ_PWM IRQ_TYPE_LEVEL_HIGH>;
            status = "ok";
        };

        pwm4: pwm@0x1F203400 {
            compatible = "sstar,pwm";
            reg = <0x1F203400 0x37>;
            #pwm-cells = <3>;
            channel = <4>;
            group = <1>;
            clocks = <&CLK_pwm>;
            clk-select = <0>;
            interrupts=<GIC_SPI INT_IRQ_PWM IRQ_TYPE_LEVEL_HIGH>;
            status = "ok";
        };

        pwm5: pwm@0x1F203440 {
            compatible = "sstar,pwm";
            reg = <0x1F203440 0x37>;
            #pwm-cells = <3>;
            channel = <5>;
            group = <1>;
            clocks = <&CLK_pwm>;
            clk-select = <0>;
            interrupts=<GIC_SPI INT_IRQ_PWM IRQ_TYPE_LEVEL_HIGH>;
            status = "ok";
        };

        pwm6: pwm@0x1F203480 {
            compatible = "sstar,pwm";
            reg = <0x1F203480 0x37>;
            #pwm-cells = <3>;
            channel = <6>;
            group = <1>;
            clocks = <&CLK_pwm>;
            clk-select = <0>;
            interrupts=<GIC_SPI INT_IRQ_PWM IRQ_TYPE_LEVEL_HIGH>;
            status = "ok";
        };

        pwm7: pwm@0x1F2034C0 {
            compatible = "sstar,pwm";
            reg = <0x1F2034C0 0x37>;
            #pwm-cells = <3>;
            channel = <7>;
            group = <1>;
            clocks = <&CLK_pwm>;
            clk-select = <0>;
            interrupts=<GIC_SPI INT_IRQ_PWM IRQ_TYPE_LEVEL_HIGH>;
            status = "ok";
        };

        pwm8: pwm@0x1F003400 {
            compatible = "sstar,pwm";
            reg = <0x1F003400 0x37>;
            #pwm-cells = <3>;
            channel = <8>;
            clocks = <&CLK_pm_pwm>;
            clk-select = <0>;
            status = "ok";
        };

        pwm9: pwm@0x1F003440 {
            compatible = "sstar,pwm";
            reg = <0x1F003440 0x37>;
            #pwm-cells = <3>;
            channel = <9>;
            clocks = <&CLK_pm_pwm>;
            clk-select = <0>;
            status = "ok";
        };

        pwm10: pwm@0x1F003480 {
            compatible = "sstar,pwm";
            reg = <0x1F003480 0x37>;
            #pwm-cells = <3>;
            channel = <10>;
            clocks = <&CLK_pm_pwm>;
            clk-select = <0>;
            status = "ok";
        };

        pwm11: pwm@0x1F0034C0 {
            compatible = "sstar,pwm";
            reg = <0x1F0034C0 0x37>;
            #pwm-cells = <3>;
            channel = <11>;
            clocks = <&CLK_pm_pwm>;
            clk-select = <0>;
            status = "ok";
        };

        ir: ir@1F007A00 {
            compatible = "sstar,ir";
            reg = <0x1F007A00 0x200>;
            clocks = <&CLK_ir>;
            interrupts = <GIC_SPI INT_FIQ_IR IRQ_TYPE_LEVEL_HIGH>,<GIC_SPI INT_FIQ_IR_RC IRQ_TYPE_LEVEL_HIGH>;
            group =<0>;
            /*
             * decode mode selection
             * FULL   1  Format: NEC
             * RAW    2  Format: NEC
             * RC5    3  Format: RC
             * SW     4  Format: /
             */
            mode = <2>;
            //choose enum rc_proto for sw mode
            protocol = <9>;
            vendor = <0x000E>;
            product = <0x3412>;
            //rc-map-table = <customer_code + command_code  input_key_code>
            rc-map-table =
                //NEC Remote Control NO.1
                <0x00A8 KEY_POWER>,          <0x00C0 KEY_F5>,            <0x00DD KEY_GREEN>,
                <0x0044 KEY_F19>,            <0x00CA KEY_UP>,            <0x00D2 KEY_DOWN>,
                <0x0099 KEY_LEFT>,           <0x00C1 KEY_RIGHT>,         <0x00CE KEY_ENTER>,
                <0x00CB KEY_BACK>,           <0x0087 KEY_HOMEPAGE>,      <0x0097 KEY_COMPOSE>,
                <0x0041 KEY_PLAYPAUSE>,      <0x000F KEY_F16>,           <0x0060 KEY_F20>,
                <0x0090 KEY_VOLUMEUP>,       <0x0098 KEY_VOLUMEDOWN>,    <0x00D1 KEY_MUTE>,
                //NEC Remote Control NO.2
                <0x8046  KEY_POWER>,          <0x8050  KEY_0>,           <0x8049  KEY_1>,
                <0x8055  KEY_2>,              <0x8059  KEY_3>,           <0x804D  KEY_4>,
                <0x8051  KEY_5>,              <0x805D  KEY_6>,           <0x8048  KEY_7>,
                <0x8054  KEY_8>,              <0x8058  KEY_9>,           <0x8047  KEY_RED>,
                <0x804B  KEY_GREEN>,          <0x8057  KEY_YELLOW>,      <0x805B  KEY_BLUE>,
                <0x8052  KEY_UP>,             <0x8013  KEY_DOWN>,        <0x8006  KEY_LEFT>,
                <0x801A  KEY_RIGHT>,          <0x800F  KEY_ENTER>,       <0x801F  KEY_CHANNELUP>,
                <0x8019  KEY_CHANNELDOWN>,    <0x8016  KEY_VOLUMEUP>,    <0x8015  KEY_VOLUMEDOWN>,
                <0x8003  KEY_PAGEUP>,         <0x8005  KEY_PAGEDOWN>,    <0x8017  KEY_HOME>,
                <0x8007  KEY_MENU>,           <0x801B  KEY_BACK>,        <0x805A  KEY_MUTE>,
                <0x800D  KEY_RECORD>,         <0x8042  KEY_HELP>,        <0x8014  KEY_INFO>,
                <0x8040  KEY_KP0>,            <0x8004  KEY_KP1>,         <0x800E  KEY_REWIND>,
                <0x8012  KEY_FORWARD>,        <0x804C  KEY_ZOOM>,        <0x8002  KEY_PREVIOUSSONG>,
                <0x801E  KEY_NEXTSONG>,       <0x8001  KEY_PLAY>,        <0x801D  KEY_PAUSE>,
                <0x8011  KEY_STOP>,           <0x8044  KEY_AUDIO>,       <0x8056  KEY_CAMERA>,
                <0x805C  KEY_CHANNEL>,        <0x8045  KEY_SLEEP>,       <0x804A  KEY_EPG>,
                <0x8010  KEY_LIST>,           <0x8053  KEY_SUBTITLE>,    <0x8041  KEY_FN_F1>,
                <0x804E  KEY_FN_F2>,          <0x800A  KEY_FN_F3>,       <0x8009  KEY_FN_F4>,
                <0x801C  KEY_FN_F5>,          <0x8008  KEY_FN_F6>,       <0x800B  KEY_F1>,
                <0x8018  KEY_F2>,             <0x8000  KEY_F3>,          <0x800C  KEY_F4>,
                <0x804F  KEY_F5>,             <0x805E  KEY_F6>,          <0x8043  KEY_F7>,
                <0x805F  KEY_F8>,             <0x80FE  KEY_POWER2>,      <0x80FF  KEY_OK>,
                //RC5 Remote Control
                <0x150C  KEY_POWER>,          <0x153F  KEY_AUX>,         <0x141D  KEY_MEDIA_REPEAT>,
                <0x141C  KEY_SHUFFLE>,        <0x100D  KEY_MUTE>,        <0x104F  KEY_F4>,
                <0x143F  KEY_F1>,             <0x112D  KEY_F2>,          <0x112E  KEY_F3>,
                <0x1010  KEY_VOLUMEUP>,       <0x1011  KEY_VOLUMEDOWN>,  <0x1521  KEY_PREVIOUSSONG>,
                <0x1520  KEY_NEXTSONG>,       <0x1536  KEY_PAUSE>,       <0x1535  KEY_PLAY>,
                <0x151F  KEY_BACK>,           <0x151E  KEY_FORWARD>,     <0x1063  KEY_MAX>,
                <0x1040  KEY_F6>,             <0x1120  KEY_CHANNELUP>,   <0x1121  KEY_CHANNELDOWN>;
            status = "ok";
        };

        sar: sar {
            compatible = "sstar,sar";
            reg = <0x1F002800 0x200>;
            clocks = <&CLK_sar>;
            ref-voltage = <1>;
            status = "ok";
        };

        vpe: vpe {
            compatible = "sigmastar,vpe";
            status = "ok";
            #ifdef CONFIG_CAM_CLK
            camclk = <CAMCLK_fclk1>;
            #else
            clocks = <&CLK_fclk1>;
            #endif
            interrupts = <GIC_SPI INT_IRQ_SC_TOP IRQ_TYPE_LEVEL_HIGH>, <GIC_SPI INT_IRQ_SC_TOP_1 IRQ_TYPE_LEVEL_HIGH>, <GIC_SPI INT_IRQ_SC_TOP_3 IRQ_TYPE_LEVEL_HIGH>;
        };

        rgn: rgn {
            compatible = "sstar,rgn";
            status = "ok";
            //Reg = <0x1F224000 0x200>;
        };
        usb2phy1_utmi: utmi@0x1f284200 {
            compatible="syscon";
            reg = <0x1f284200 0x200>;
            reg-io-width = <2>;
        };

        usb2phy1_bc: bc@0x1f284400 {
            compatible="syscon";
            reg = <0x1f284400 0x200>;
            reg-io-width = <2>;
        };

        usb2phy1_usbc: usbc@0x1f284600 {
            compatible="syscon";
            reg = <0x1f284600 0x200>;
            reg-io-width = <2>;
        };

        usb2phy1_uhc: uhc@0x1f284800 {
            compatible="syscon";
            reg = <0x1f284800 0x200>;
            reg-io-width = <2>;
        };

        sstar_u2phy: sstar-usb2-phy {
            compatible = "sstar,u2phy";
            #address-cells = <1>;
            #size-cells = <1>;
            ranges;
            status = "ok";

            sstar_u2phy1: u2phy1 {
                syscon-utmi = <&usb2phy1_utmi>;
                syscon-uhc = <&usb2phy1_uhc>;
                syscon-usbc = <&usb2phy1_usbc>;
                syscon-bc = <&usb2phy1_bc>;
                //utmi_dp_dm_swap = <0>;
                #phy-cells = <0>;
                status = "ok";
            };
        };
        Sstar-ehci-1 {
            compatible = "Sstar-ehci-1";
            reg-names = "ehc_base";
            reg = <0x1f284800 0x200>;
            syscon-utmi = <&usb2phy1_utmi>;
            syscon-usbc = <&usb2phy1_usbc>;
            syscon-bc = <&usb2phy1_bc>;
            // clocks = <&CLK_utmi>;
            interrupts = <GIC_SPI INT_IRQ_UHC IRQ_TYPE_LEVEL_HIGH>;
            phys = <&sstar_u2phy1>;
            phy-names = "usb";
            support_high_2g_access_patch;
            //power-enable-pad = <PAD_GPIO8>;
            status = "ok";
        };
        msb250x-udc {
            compatible = "sstar,msb250x-udc";
            interrupts = <GIC_SPI INT_IRQ_OTG IRQ_TYPE_LEVEL_HIGH>;
            status = "ok";
        };

        ive0: ive@0x1F2A3C00 {
            compatible = "sstar,infinity-ive";
            reg = <0x1F2A3C00 0x100>,<0x1F2A3E00 0x100>,<0x1F2A4000 0x100>;
            interrupts = <GIC_SPI INT_IRQ_IVE IRQ_TYPE_LEVEL_HIGH>;
            clocks = <&CLK_ive>;
            status = "ok";
        };

    };
};

&clks {
    #include "../../../../drivers/sstar/include/iford/reg_clks.h"
    #include "iford-clks.dtsi"
};

